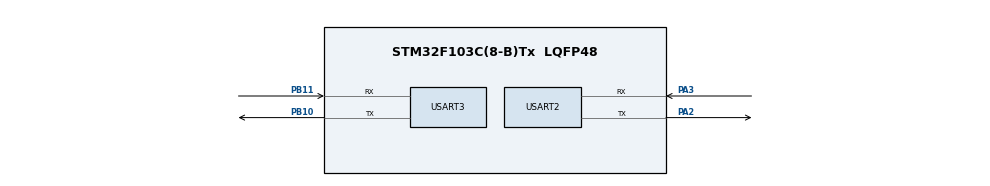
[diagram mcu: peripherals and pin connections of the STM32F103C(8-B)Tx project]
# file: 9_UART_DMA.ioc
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Mcu.Family=STM32F1
NVIC.USART3_IRQn=true\:0\:0\:false\:false\:true\:true\:true
NVIC.DMA1_Channel6_IRQn=true\:0\:0\:false\:false\:true\:false\:true
Dma.USART3_RX.1.Mode=DMA_CIRCULAR
PD1-OSC_OUT.Mode=HSE-External-Oscillator
PB10.Mode=Asynchronous
Dma.USART2_RX.0.Direction=DMA_PERIPH_TO_MEMORY
Dma.USART3_RX.1.MemDataAlignment=DMA_MDATAALIGN_BYTE
PD0-OSC_IN.Signal=RCC_OSC_IN
PB11.Signal=USART3_RX
NVIC.USART2_IRQn=true\:0\:0\:false\:false\:true\:true\:true
ProjectManager.StackSize=0x400
Dma.USART2_RX.0.Mode=DMA_CIRCULAR
PD1-OSC_OUT.Signal=RCC_OSC_OUT
NVIC.DMA1_Channel3_IRQn=true\:0\:0\:false\:false\:true\:false\:true
PA13.Signal=SYS_JTMS-SWDIO
PA3.Mode=Asynchronous
Dma.USART3_RX.1.MemInc=DMA_MINC_ENABLE
PB11.Mode=Asynchronous
ProjectManager.TargetToolchain=STM32CubeIDE
Dma.USART3_RX.1.Instance=DMA1_Channel3
Dma.USART2_RX.0.Priority=DMA_PRIORITY_LOW
Dma.USART2_RX.0.PeriphDataAlignment=DMA_PDATAALIGN_BYTE
Dma.USART3_RX.1.PeriphDataAlignment=DMA_PDATAALIGN_BYTE
PB10.Signal=USART3_TX
PD0-OSC_IN.Mode=HSE-External-Oscillator
board=custom
RCC.APB2Freq_Value=8000000
Dma.USART2_RX.0.MemDataAlignment=DMA_MDATAALIGN_BYTE
Dma.USART3_RX.1.Priority=DMA_PRIORITY_LOW
PA14.Mode=Serial_Wire
Dma.USART2_RX.0.Instance=DMA1_Channel6
PA13.Mode=Serial_Wire
Mcu.Name=STM32F103C(8-B)Tx
Dma.USART2_RX.0.MemInc=DMA_MINC_ENABLE
PA2.Signal=USART2_TX
Mcu.Package=LQFP48
Dma.USART2_RX.0.PeriphInc=DMA_PINC_DISABLE
USART2.VirtualMode=VM_ASYNC
USART3.VirtualMode=VM_ASYNC
Dma.USART3_RX.1.Direction=DMA_PERIPH_TO_MEMORY
PA14.Signal=SYS_JTCK-SWCLK
ProjectManager.HeapSize=0x200
NVIC.PriorityGroup=NVIC_PRIORITYGROUP_4
Dma.Request1=USART3_RX
PA2.Mode=Asynchronous
Dma.Request0=USART2_RX
RCC.APB1Freq_Value=8000000
Dma.USART3_RX.1.PeriphInc=DMA_PINC_DISABLE
PA3.Signal=USART2_RX

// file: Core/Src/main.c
/* USER CODE BEGIN Header */
/**
 ******************************************************************************
 * @file           : main.c
 * @brief          : Main program body
 ******************************************************************************
 * @attention
 *
 * <h2><center>&copy; Copyright (c) 2021 STMicroelectronics.
 * All rights reserved.</center></h2>
 *
 * This software component is licensed by ST under BSD 3-Clause license,
 * the "License"; You may not use this file except in compliance with the
 * License. You may obtain a copy of the License at:
 *                        opensource.org/licenses/BSD-3-Clause
 *
 ******************************************************************************
 */
/* USER CODE END Header */
#include "main.h"

UART_HandleTypeDef huart2;
UART_HandleTypeDef huart3;
DMA_HandleTypeDef hdma_usart2_rx;
DMA_HandleTypeDef hdma_usart3_rx;

/* USER CODE BEGIN PV */
uint8_t RX2, RX3, TX_Data = 32;
/* USER CODE END PV */

void SystemClock_Config(void);
static void MX_GPIO_Init(void);
static void MX_DMA_Init(void);
static void MX_USART2_UART_Init(void);
static void MX_USART3_UART_Init(void);
/* USER CODE BEGIN PFP */
void HAL_UART_RxCpltCallback(UART_HandleTypeDef *huart) {
	if (huart->Instance == huart3.Instance) {
		HAL_UART_Transmit_IT(&huart3, &RX3, 1);
	}
}
/* USER CODE END PFP */

int main(void) {

	/* MCU Configuration--------------------------------------------------------*/

	/* Reset of all peripherals, Initializes the Flash interface and the Systick. */
	HAL_Init();

	/* Configure the system clock */
	SystemClock_Config();

	/* Initialize all configured peripherals */
	MX_GPIO_Init();
	MX_DMA_Init();
	MX_USART2_UART_Init();
	MX_USART3_UART_Init();
	/* USER CODE BEGIN 2 */
	HAL_UART_Receive_DMA(&huart2, &RX2, 1);
	HAL_UART_Receive_DMA(&huart3, &RX3, 1);
	/* USER CODE END 2 */

	/* Infinite loop */
	while (1) {
		HAL_UART_Transmit_IT(&huart2, &TX_Data, 1);
		TX_Data++;
		HAL_Delay(1000);
	}
}

void SystemClock_Config(void) {
	RCC_OscInitTypeDef RCC_OscInitStruct = { 0 };
	RCC_ClkInitTypeDef RCC_ClkInitStruct = { 0 };

	/** Initializes the RCC Oscillators according to the specified parameters
	 * in the RCC_OscInitTypeDef structure.
	 */
	RCC_OscInitStruct.OscillatorType = RCC_OSCILLATORTYPE_HSI;
	RCC_OscInitStruct.HSIState = RCC_HSI_ON;
	RCC_OscInitStruct.HSICalibrationValue = RCC_HSICALIBRATION_DEFAULT;
	RCC_OscInitStruct.PLL.PLLState = RCC_PLL_NONE;
	if (HAL_RCC_OscConfig(&RCC_OscInitStruct) != HAL_OK) {
		Error_Handler();
	}
	/** Initializes the CPU, AHB and APB buses clocks
	 */
	RCC_ClkInitStruct.ClockType = RCC_CLOCKTYPE_HCLK | RCC_CLOCKTYPE_SYSCLK
			| RCC_CLOCKTYPE_PCLK1 | RCC_CLOCKTYPE_PCLK2;
	RCC_ClkInitStruct.SYSCLKSource = RCC_SYSCLKSOURCE_HSI;
	RCC_ClkInitStruct.AHBCLKDivider = RCC_SYSCLK_DIV1;
	RCC_ClkInitStruct.APB1CLKDivider = RCC_HCLK_DIV1;
	RCC_ClkInitStruct.APB2CLKDivider = RCC_HCLK_DIV1;

	if (HAL_RCC_ClockConfig(&RCC_ClkInitStruct, FLASH_LATENCY_0) != HAL_OK) {
		Error_Handler();
	}
}

static void MX_USART2_UART_Init(void) {

	huart2.Instance = USART2;
	huart2.Init.BaudRate = 115200;
	huart2.Init.WordLength = UART_WORDLENGTH_8B;
	huart2.Init.StopBits = UART_STOPBITS_1;
	huart2.Init.Parity = UART_PARITY_NONE;
	huart2.Init.Mode = UART_MODE_TX_RX;
	huart2.Init.HwFlowCtl = UART_HWCONTROL_NONE;
	huart2.Init.OverSampling = UART_OVERSAMPLING_16;
	if (HAL_UART_Init(&huart2) != HAL_OK) {
		Error_Handler();
	}

}

static void MX_USART3_UART_Init(void) {

	huart3.Instance = USART3;
	huart3.Init.BaudRate = 115200;
	huart3.Init.WordLength = UART_WORDLENGTH_8B;
	huart3.Init.StopBits = UART_STOPBITS_1;
	huart3.Init.Parity = UART_PARITY_NONE;
	huart3.Init.Mode = UART_MODE_TX_RX;
	huart3.Init.HwFlowCtl = UART_HWCONTROL_NONE;
	huart3.Init.OverSampling = UART_OVERSAMPLING_16;
	if (HAL_UART_Init(&huart3) != HAL_OK) {
		Error_Handler();
	}

}

static void MX_DMA_Init(void) {

	/* DMA controller clock enable */
	__HAL_RCC_DMA1_CLK_ENABLE();

	/* DMA interrupt init */
	/* DMA1_Channel3_IRQn interrupt configuration */
	HAL_NVIC_SetPriority(DMA1_Channel3_IRQn, 0, 0);
	HAL_NVIC_EnableIRQ(DMA1_Channel3_IRQn);
	/* DMA1_Channel6_IRQn interrupt configuration */
	HAL_NVIC_SetPriority(DMA1_Channel6_IRQn, 0, 0);
	HAL_NVIC_EnableIRQ(DMA1_Channel6_IRQn);

}

static void MX_GPIO_Init(void) {

	/* GPIO Ports Clock Enable */
	__HAL_RCC_GPIOD_CLK_ENABLE();
	__HAL_RCC_GPIOA_CLK_ENABLE();
	__HAL_RCC_GPIOB_CLK_ENABLE();

}

void Error_Handler(void) {
	__disable_irq();
	while (1) {
	}
}

/************************ (C) COPYRIGHT STMicroelectronics *****END OF FILE****/
